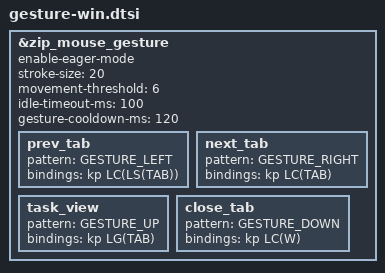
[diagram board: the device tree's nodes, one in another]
&zip_mouse_gesture {
    enable-eager-mode;
    stroke-size = <20>;
    movement-threshold = <6>;
    idle-timeout-ms = <100>;
    gesture-cooldown-ms = <120>;

    prev_tab   { pattern = <GESTURE_LEFT>;  bindings = <&kp LC(LS(TAB))>; };
    next_tab   { pattern = <GESTURE_RIGHT>; bindings = <&kp LC(TAB)>;     };
    task_view  { pattern = <GESTURE_UP>;    bindings = <&kp LG(TAB)>;      };
    close_tab  { pattern = <GESTURE_DOWN>;  bindings = <&kp LC(W)>;       };
};
